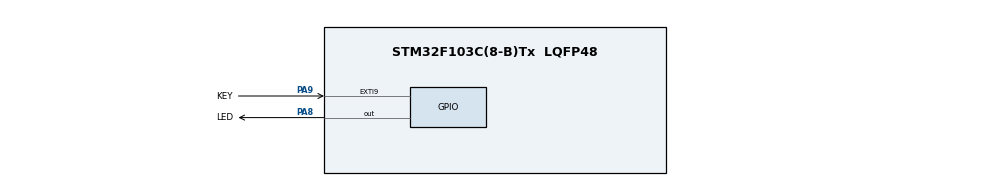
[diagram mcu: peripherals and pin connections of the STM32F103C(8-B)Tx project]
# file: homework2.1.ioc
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Mcu.Family=STM32F1
Mcu.Name=STM32F103C(8-B)Tx
Mcu.Package=LQFP48
NVIC.EXTI9_5_IRQn=true\:15\:0\:true\:false\:true\:true\:true\:true
NVIC.PriorityGroup=NVIC_PRIORITYGROUP_4
NVIC.TIM3_IRQn=true\:14\:0\:true\:false\:true\:true\:true\:true
PA13.Mode=Serial_Wire
PA13.Signal=SYS_JTMS-SWDIO
PA14.Mode=Serial_Wire
PA14.Signal=SYS_JTCK-SWCLK
PA8.GPIO_Label=LED
PA8.Signal=GPIO_Output
PA9.GPIO_Label=KEY
PA9.GPIO_ModeDefaultEXTI=GPIO_MODE_IT_RISING_FALLING
PA9.GPIO_PuPd=GPIO_PULLUP
PA9.Signal=GPXTI9
ProjectManager.HeapSize=0x200
ProjectManager.StackSize=0x400
ProjectManager.TargetToolchain=MDK-ARM V5.32
RCC.APB1Freq_Value=8000000
RCC.APB2Freq_Value=8000000
TIM3.Period=9999
TIM3.Prescaler=7
VP_TIM3_VS_ClockSourceINT.Mode=Internal
board=custom

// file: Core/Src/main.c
/* USER CODE BEGIN Header */
/**
 ******************************************************************************
 * @file           : main.c
 * @brief          : Main program body
 ******************************************************************************
 * @attention
 *
 * Copyright (c) 2026 STMicroelectronics.
 * All rights reserved.
 *
 * This software is licensed under terms that can be found in the LICENSE file
 * in the root directory of this software component.
 * If no LICENSE file comes with this software, it is provided AS-IS.
 *
 ******************************************************************************
 */
/* USER CODE END Header */
#include "main.h"
#include "tim.h"
#include "gpio.h"

/* USER CODE BEGIN PV */
volatile uint8_t led_state = 0, key_state = 1; // 上拉初始高电平
volatile uint16_t key_long_pressed_times = 0;
volatile uint32_t last_time = 0;
/* USER CODE END PV */

void SystemClock_Config(void);
/* USER CODE BEGIN PFP */
void HAL_GPIO_EXTI_Callback(uint16_t GPIO_Pin);
void HAL_TIM_PeriodElapsedCallback(TIM_HandleTypeDef *htim);
/* USER CODE END PFP */

/* USER CODE BEGIN 0 */
void HAL_GPIO_EXTI_Callback(uint16_t GPIO_Pin)
{
    if (GPIO_Pin == KEY_Pin) // 按下
    {
        __HAL_TIM_SET_COUNTER(&htim3, 0);
        HAL_TIM_Base_Start_IT(&htim3);
    }
}
void HAL_TIM_PeriodElapsedCallback(TIM_HandleTypeDef *htim)
{
    if (htim->Instance == TIM3)
    {
        HAL_TIM_Base_Stop_IT(&htim3);
        if (HAL_GPIO_ReadPin(KEY_GPIO_Port, KEY_Pin) != key_state)
        {
            key_state = HAL_GPIO_ReadPin(KEY_GPIO_Port, KEY_Pin);
            if (key_state == 0) // 按下
            {
                last_time = HAL_GetTick();
            }
            else if (key_state == 1) // 松开
            {
                uint32_t current_time = HAL_GetTick();
                if (current_time - last_time < 1000)
                {
                    if (led_state == 0)
                    {
                        HAL_GPIO_WritePin(LED_GPIO_Port, LED_Pin, GPIO_PIN_SET);
                        led_state = 1;
                    }
                    else if (led_state == 1)
                    {
                        HAL_GPIO_WritePin(LED_GPIO_Port, LED_Pin, GPIO_PIN_RESET);
                        led_state = 0;
                    }
                }
                else if (current_time - last_time >= 1000)
                {
                    key_long_pressed_times++;
                }
            }
            __HAL_GPIO_EXTI_CLEAR_IT(KEY_Pin);
        }
    }
}
/* USER CODE END 0 */

int main(void)
{

  /* MCU Configuration--------------------------------------------------------*/

  /* Reset of all peripherals, Initializes the Flash interface and the Systick. */
  HAL_Init();

  /* Configure the system clock */
  SystemClock_Config();

  /* Initialize all configured peripherals */
  MX_GPIO_Init();
  MX_TIM3_Init();

  /* Infinite loop */
  /* USER CODE BEGIN WHILE */
    while (1)
    {
        while (key_long_pressed_times % 2 == 1)
        {
            HAL_GPIO_TogglePin(LED_GPIO_Port, LED_Pin);
            HAL_Delay(100);
        }
        // 结束闪烁， 恢复状态
        if (led_state == 0)
        {
            HAL_GPIO_WritePin(LED_GPIO_Port, LED_Pin, GPIO_PIN_RESET);
        }
        else if (led_state == 1)
        {
            HAL_GPIO_WritePin(LED_GPIO_Port, LED_Pin, GPIO_PIN_SET);
        }
    /* USER CODE END WHILE */

    }
}

void SystemClock_Config(void)
{
  RCC_OscInitTypeDef RCC_OscInitStruct = {0};
  RCC_ClkInitTypeDef RCC_ClkInitStruct = {0};

  /** Initializes the RCC Oscillators according to the specified parameters
  * in the RCC_OscInitTypeDef structure.
  */
  RCC_OscInitStruct.OscillatorType = RCC_OSCILLATORTYPE_HSI;
  RCC_OscInitStruct.HSIState = RCC_HSI_ON;
  RCC_OscInitStruct.HSICalibrationValue = RCC_HSICALIBRATION_DEFAULT;
  RCC_OscInitStruct.PLL.PLLState = RCC_PLL_NONE;
  if (HAL_RCC_OscConfig(&RCC_OscInitStruct) != HAL_OK)
  {
    Error_Handler();
  }

  /** Initializes the CPU, AHB and APB buses clocks
  */
  RCC_ClkInitStruct.ClockType = RCC_CLOCKTYPE_HCLK|RCC_CLOCKTYPE_SYSCLK
                              |RCC_CLOCKTYPE_PCLK1|RCC_CLOCKTYPE_PCLK2;
  RCC_ClkInitStruct.SYSCLKSource = RCC_SYSCLKSOURCE_HSI;
  RCC_ClkInitStruct.AHBCLKDivider = RCC_SYSCLK_DIV1;
  RCC_ClkInitStruct.APB1CLKDivider = RCC_HCLK_DIV1;
  RCC_ClkInitStruct.APB2CLKDivider = RCC_HCLK_DIV1;

  if (HAL_RCC_ClockConfig(&RCC_ClkInitStruct, FLASH_LATENCY_0) != HAL_OK)
  {
    Error_Handler();
  }
}

void Error_Handler(void)
{
    __disable_irq();
    while (1)
    {
    }
}
